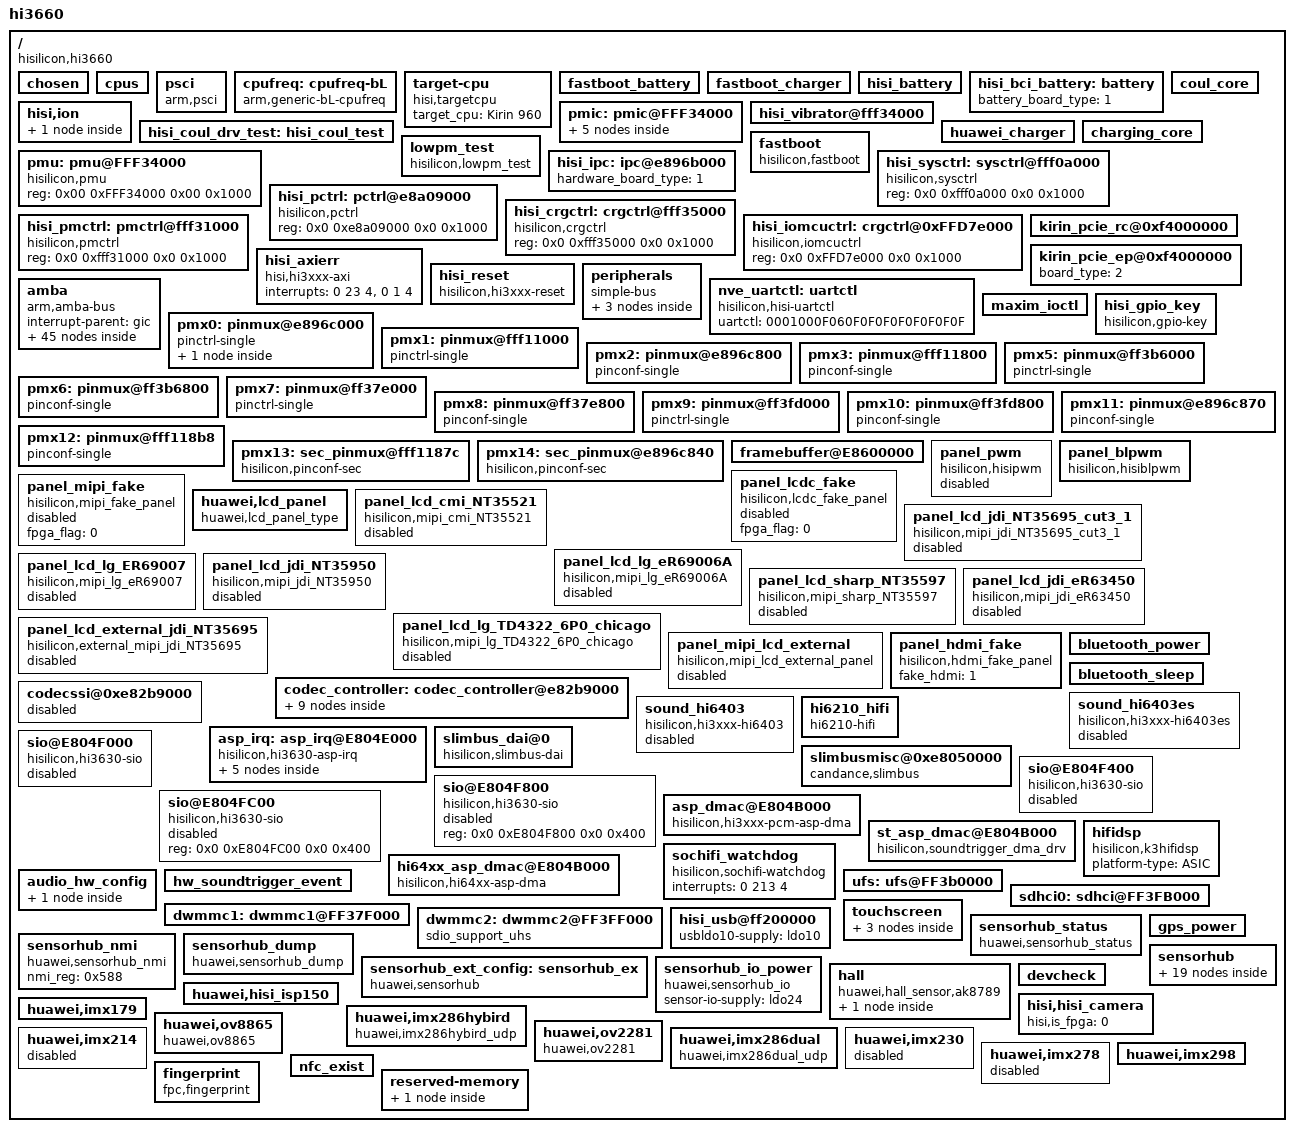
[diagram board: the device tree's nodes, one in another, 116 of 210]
/**
 * Copyright (C) 2014 Hisilicon Ltd.
 *
 *  This program is free software; you can redistribute it and/or modify
 *  it under the terms of the GNU General Public License version 2 as
 *  publishhed by the Free Software Foundation.
 */

/dts-v1/;
/include/ "fastboot.dtsi"
/include/ "hi3660_udp_default_pin.dtsi"
/include/ "hi3660_udp_default_modem_pin.dtsi"
/include/ "hisi_3660_cci.dtsi"
/include/ "hisi_3660_gic.dtsi"
/include/ "hisi_3660_timer.dtsi"
/include/ "hisi_3660.dtsi"
/include/ "hisi_3660_i2c.dtsi"
/include/ "hisi_64xx_codec.dtsi"
/include/ "hi3660_udp_default_hi6402_pin.dtsi"
/include/ "hi3660_udp_default_sec_pin.dtsi"
/include/ "hisi_bci_battery.dtsi"
/include/ "hisi_battery.dtsi"
/include/ "huawei_charger.dtsi"
/include/ "hisi_coul.dtsi"
/include/ "huawei_soft_isc.dtsi"
/include/ "fastboot_battery.dtsi"
/include/ "fastboot_charger.dtsi"
/include/ "default_3000_68k_4352.dtsi"
/include/ "hisi_3660_thermal.dtsi"
/include/ "hisi_power_ip_test.dtsi"
/include/ "huawei_devdetect.dtsi"
/include/ "hisi_3660_cpu.dtsi"
/include/ "huawei_usbswitch.dtsi"
/include/ "huawei_usbpd.dtsi"
/include/ "huawei_gps.dtsi"
/include/ "hisi_3660_framebuffer.dtsi"
/include/ "modem/hisi_modem_balong.dtsi"
/include/ "hisi_6421v500_pmic_led.dtsi"
/include/ "hisi_rtc.dtsi"
/include/ "hisi_3660_vibrator.dtsi"
/include/ "hisi_soundtrigger_event.dtsi"
/include/ "huawei_audio.dtsi"
/include/ "huawei_smartpa.dtsi"
/include/ "huawei_touchscreen.dtsi"
/include/ "hisi_3660_pca6416.dtsi"
/include/ "huawei_bluetooth.dtsi"

/ {
	#address-cells = <2>;
	#size-cells = <2>;
	model = "hi3660";
	compatible = "hisilicon,hi3660";
	interrupt-parent = <&gic>;
	hisi,boardid = <5 0 0 0>;
	hisi,boardname = "hi3660_udp_default";
	hisi,modem_id = <0x3AF5FC00>;
	hisi,product_id = <0x3AF5FC00>;

	chosen{};

	cpus {
		status = "ok";
	};

        psci {
                compatible      = "arm,psci";
                method          = "smc";
                cpu_suspend     = <0xc4000001>;
                cpu_off         = <0x84000002>;
                cpu_on          = <0xc4000003>;
                system_off      = <0x84000008>;
                system_reset    = <0x84000009>;
        };

	/* cpufreq  device */
	cpufreq: cpufreq-bL {
		compatible = "arm,generic-bL-cpufreq";
		status = "ok";
	};

	target-cpu {
		compatible = "hisi,targetcpu";
		target_cpu = "Kirin 960";
	};

	fastboot_battery:fastboot_battery {
		status = "ok";
	};
	fastboot_charger:fastboot_charger {
		hw_charger_type = <4>;
		chip_i2c_num = <6>;
		status = "ok";
	};
	hisi_battery:hisi_battery {
		status = "ok";
	};
	hisi_bci_battery:battery {
		battery_board_type = <1>; /*0:sft 1:udp 2:asic*/
		status = "ok";
	};
	coul_core:coul_core {
		adc_batt_id = <6>;
		adc_batt_temp = <10>;
		status = "ok";
	};

	hisi,ion {
		heap_sec_iris@18 {
				status = "disable";
			};
	};

	pmic:pmic@FFF34000{
		gpios = <&gpio27 6 0>;
		hisilicon,pmic_fpga_flag=<0>;
		pmic_led: pmic_led@a0 {
			status = "ok";
		};
		pmic_rtc: pmic_rtc@a0 {
			status = "ok";
		};
		ponkey:ponkey@b1{
			status = "ok";
		};
		hi6421v500_coul: hi6421v500_coul@1 {
			status = "ok";
		};
		usbvbus {
			status = "ok";
		};
	};

	hisi_vibrator@fff34000 {
		status = "ok";
	};
	hisi_coul_drv_test:hisi_coul_test {
		status = "ok";
	};
	huawei_charger: huawei_charger {
		status = "ok";
	};
	charging_core:charging_core {
		status = "ok";
		iterm = <160>;
		iin_usb = <470>;
		ichg_usb = <500>;
		ichg_fcp = <3500>;
		iin_fcp = <2000>;
		ichg_ac = <2100>;
		iin_ac = <2000>;
		inductance_para =
			"-32767", "15", "1900", "0",
			"15", "32767", "1900", "0";
	};

	fastboot {
		compatible = "hisilicon,fastboot";
		i2c3-pin = <0>;
		gpio-keyup = <205>;
		gpio-keydown = <202>;
		/*EMU_TYPE 0,FPGA 1,UDP 2,PRODUCT 3*/
		uart-board-type = <2>;
		/*UDP_TYPE 0,PRODUCT 1,FPGA 2,EMU 3*/
		lpm3-board-type = <0>;
		jtagtosd-board-type = <0>;
		motor-vib_type = <0>;

		i2c-select = <1>;
		i2c-sel0-gpio = <44>;
		i2c-sel1-gpio = <45>;
		i2c-sel0-val = <0>;
		i2c-sel1-val = <0>;
	};

	pmu: pmu@FFF34000 {
		compatible = "hisilicon,pmu";
		reg = <0x00 0xFFF34000 0x00 0x1000>;
		status = "ok";
	};

	lowpm_test {
		compatible = "hisilicon,lowpm_test";
		sr_plat_flag = <1>;
		reg = <0x0 0xfff32000 0x0 0x1000>;
		status = "ok";
	};
	hisi_ipc: ipc@e896b000 {
		hardware_board_type = <1>; /* 1:udp & fpga 0:asic */
		status = "ok";
	};

        hisi_sysctrl: sysctrl@fff0a000 {
                compatible = "hisilicon,sysctrl";
                reg = <0x0 0xfff0a000 0x0 0x1000>;
                status = "ok";
        };

        hisi_pctrl: pctrl@e8a09000 {
                compatible = "hisilicon,pctrl";
                reg = <0x0 0xe8a09000 0x0 0x1000>;
                status = "ok";
        };

        hisi_crgctrl: crgctrl@fff35000 {
                compatible = "hisilicon,crgctrl";
                reg = <0x0 0xfff35000 0x0 0x1000>;
                status = "ok";
        };

	hisi_iomcuctrl: crgctrl@0xFFD7e000 {
                compatible = "hisilicon,iomcuctrl";
                reg = <0x0 0xFFD7e000 0x0 0x1000>;
                status = "ok";
        };

        hisi_pmctrl: pmctrl@fff31000 {
                compatible = "hisilicon,pmctrl";
                reg = <0x0 0xfff31000 0x0 0x1000>;
                status = "ok";
        };

	kirin_pcie_rc@0xf4000000 {
		board_type = <2>;
		wl_power = <150>;

		/*EP Device Description: here describe BCM 4359*/
		ep_vend_id = <0x14e4>;
		ep_dev_id = <0x4355>;
		ep_ltr_latency = <0x10031003>;
		ep_l1ss_ctrl2 = <0x61>;
		status = "ok";
	};

	kirin_pcie_ep@0xf4000000 {
		board_type = <2>;
	};

	hisi_axierr {
	        compatible = "hisi,hi3xxx-axi";
	        interrupts = <0 23 4>, <0 1 4>;
	        status = "ok";
        };

    hisi_reset {
            compatible = "hisilicon,hi3xxx-reset";
            status = "ok";
        };

	peripherals {
		compatible = "simple-bus";
		#address-cells = <1>;
		#size-cells = <1>;
		ranges = <0x0 0x00000000 0x0 0xffffffff>;

		clk6250khz: clk6250khz {
			compatible = "fixed-clock";
			#clock-cells = <0>;
			clock-frequency = <6297600>;
			clock-output-names = "clk6250khz";
		};
/*
		clk4800khz: clk4800khz {
			compatible = "fixed-clock";
			#clock-cells = <0>;
			clock-frequency = <32768>;
			clock-output-names = "clk4800khz";
		};
*/

		dma0: dma@fdf30000 {
			status = "ok";
		};

		iomcu_dma: dma@ffd77000 {
			status = "ok";
		};

	};
	nve_uartctl:uartctl {
		compatible = "hisilicon,hisi-uartctl";
		uartctl = "0001000F060F0F0F0F0F0F0F0F";
	};
	amba {
		#address-cells = <2>;
		#size-cells = <2>;
		compatible = "arm,amba-bus";
		interrupt-parent = <&gic>;
		ranges;

		/*rtc0: rtc@FFF04000 {
				compatible = "arm,rtc-pl031", "arm,primecell";
				reg = <0xfff04000 0x1000>;
				interrupts = <0 46 0x4>;
				clocks = <&pclk>;
				clock-names = "apb_pclk";
				status = "ok";
		};*/

		/*rtc1: rtc@FFF05000 {
				compatible = "arm,rtc-pl031", "arm,primecell";
				reg = <0xfff05000 0x1000>;
				interrupts = <0 47 0x4>;
				clocks = <&pclk>;
				clock-names = "apb_pclk";
				status = "ok";
		};*/

		watchdog0 {
			compatible = "arm,sp805", "arm,primecell";
			reg = <0x0 0xe8a06000 0x0 0x1000>;
			default-timeout = <24>;
			interrupts = <0 44 4>;
			clocks = <&pclk_gate_wd0 &pclk>;
			clock-names = "pclk_wd0", "apb_pclk";
			status = "disabled";
		};

                iomcu_watchdog: watchdog@ffd7c000{
                        compatible = "hisilicon,iomcu-watchdog";
                        reg = <0x0 0xFFD7C000 0x0 0x1000>;
                        status = "ok";
                };

		/*wdt1@e8a07000 {
			compatible = "arm,sp805", "arm,primecell";
			reg = <0x0 0xe8a07000 0x0 0x1000>;
			interrupts = <0 45 4>;
			clocks = <&pclk_gate_wd0 &pclk>;
			clock-names = "pclk_wd0", "apb_pclk";
		};*/

		serial0: uart@fdf02000 {
			pinctrl-names = "default", "idle";
			pinctrl-0 = <&gpio053_pmx_func &gpio054_pmx_func &gpio053_cfg_func &gpio054_cfg_func>;
			pinctrl-1 = <&gpio053_pmx_idle &gpio054_pmx_idle &gpio053_cfg_idle &gpio054_cfg_idle>;
			dma-names = "", "";
			dmas = <>;
			clock-rate = <0 19200000>;
			console-fifo-enable = <1>;
			console-fifo-size = <262144>;/* 256k */
			console-fifo-cpuon = <3>;
			status = "ok";
		};

		serial1: uart@fdf00000 {
			pinctrl-names = "default", "idle";
			pinctrl-0 = <>;
			pinctrl-1 = <>;
			clock-rate = <0 160000000>;
			status = "disabled";
			reset-enable-flag = <1>;
		};

		serial2: uart@fdf03000 {
			pinctrl-names = "default", "idle";
			pinctrl-0 = <>;
			pinctrl-1 = <>;
			clock-rate = <0 160000000>;
			status = "ok";
			reset-enable-flag = <1>;
		};

		serial3: uart@ffd74000 {
			pinctrl-names = "default", "idle";
			pinctrl-0 = <&gpio057_pmx_func &gpio058_pmx_func &gpio059_pmx_func &gpio060_pmx_func &gpio057_cfg_func &gpio058_cfg_func &gpio059_cfg_func &gpio060_cfg_func>;
			pinctrl-1 = <&gpio057_pmx_idle &gpio058_pmx_idle &gpio059_pmx_idle &gpio060_pmx_idle &gpio057_cfg_idle &gpio058_cfg_idle &gpio059_cfg_idle &gpio060_cfg_idle>;
			dma-names = "", "";
			dmas = <>;
			clock-rate = <0 100000000>;
			status = "ok";
			reset-enable-flag = <0>;
		};

		serial4: uart@fdf01000 {
			pinctrl-names = "default", "idle";
			pinctrl-0 = <&gpio061_pmx_func &gpio062_pmx_func &gpio063_pmx_func &gpio064_pmx_func &gpio061_cfg_func &gpio062_cfg_func &gpio063_cfg_func &gpio064_cfg_func>;
			pinctrl-1 = <&gpio061_pmx_idle &gpio062_pmx_idle &gpio063_pmx_idle &gpio064_pmx_idle &gpio061_cfg_idle &gpio062_cfg_idle &gpio063_cfg_idle &gpio064_cfg_idle>;
			clock-rate = <0 160000000>;
			status = "ok";
			reset-enable-flag = <1>;
		};

		serial5: uart@fdf05000 {
			pinctrl-names = "default", "idle";
			pinctrl-0 = <>;
			pinctrl-1 = <>;
			clock-rate = <0 160000000>;
			status = "ok";
			reset-enable-flag = <1>;
		};

		serial6: uart@fff32000 {
			pinctrl-names = "default", "idle";
			pinctrl-0 = <&gpio055_pmx_func &gpio056_pmx_func &gpio055_cfg_func &gpio056_cfg_func>;
			pinctrl-1 = <&gpio055_pmx_idle &gpio056_pmx_idle &gpio055_cfg_idle &gpio056_cfg_idle>;
			clock-rate = <0 19200000>;
			console-fifo-enable = <1>;
			console-fifo-size = <262144>;/* 256k */
			console-fifo-cpuon = <3>;
			status = "ok";
		};
		dx_cc63p: dx_cc63p@fdf0e000 {
			compatible = "dx,cc63p";
			reg = <0x0 0xfdf0e000 0x0 0x1000>;
			interrupt-parent = <&gic>;
			interrupts = <0 135 4>;
			status = "ok";
		};

		spi0: spi@ffd70000 {
			status = "ok";
			clock-rate = <0 32000000>;
			pinctrl-names = "default", "idle";
			pinctrl-0 = <&gpio044_pmx_func &gpio045_pmx_func &gpio046_pmx_func &gpio044_cfg_func &gpio045_cfg_func
					&gpio046_cfg_func>;
			pinctrl-1 = <&gpio044_pmx_idle &gpio045_pmx_idle &gpio046_pmx_idle &gpio044_cfg_idle &gpio045_cfg_idle
					&gpio046_cfg_idle>;
			spi_dev0: spi_dev0@0 {
					compatible = "spi_dev0";
					spi-max-frequency = <30000000>;
					reg = <0>;
					pl022,com-mode = <0>;
					pl022,interface = <0>;
					pl022,rx-level-trig = <3>;
					pl022,tx-level-trig = <3>;
					pl022,ctrl-len = <7>;
					pl022,wait-state = <0>;
					pl022,duplex = <0>;
					pl022,slave-tx-disable = <0>;
			};

			spi_dev1: spi_dev1@1 {
					compatible = "spi_dev1";
					spi-max-frequency = <13000000>;
					reg = <1>;
					pl022,com-mode = <1>;
					pl022,interface = <0>;
					pl022,rx-level-trig = <3>;
					pl022,tx-level-trig = <3>;
					pl022,ctrl-len = <7>;
					pl022,wait-state = <0>;
					pl022,duplex = <0>;
					pl022,slave-tx-disable = <0>;
			};

			spi_dev2: spi_dev2@2 {
					compatible = "spi_dev2";
					spi-max-frequency = <13000000>;
					reg = <2>;
					pl022,com-mode = <2>;
					pl022,interface = <0>;
					pl022,rx-level-trig = <3>;
					pl022,tx-level-trig = <3>;
					pl022,ctrl-len = <7>;
					pl022,wait-state = <0>;
					pl022,duplex = <0>;
					pl022,slave-tx-disable = <0>;
			};

			spi_dev3: spi_dev3@3 {
					compatible = "spi_dev3";
					spi-max-frequency = <13000000>;
					reg = <3>;
					pl022,com-mode = <0>;
					pl022,interface = <0>;
					pl022,rx-level-trig = <3>;
					pl022,tx-level-trig = <3>;
					pl022,ctrl-len = <7>;
					pl022,wait-state = <0>;
					pl022,duplex = <0>;
					pl022,slave-tx-disable = <0>;
			};
		};

		spi1: spi@fdf08000 {
			/* secure */
			status = "ok";
			clock-rate = <0 46000000>;
			pinctrl-names = "default", "idle";
			pinctrl-0 = <>;
			pinctrl-1 = <>;
			spi_dev10: spi_dev10@10 {
					compatible = "spi_dev10";
					spi-max-frequency = <24000000>;
					reg = <0>;
					pl022,com-mode = <0>;
					pl022,interface = <0>;
					pl022,rx-level-trig = <3>;
					pl022,tx-level-trig = <3>;
					pl022,ctrl-len = <7>;
					pl022,wait-state = <0>;
					pl022,duplex = <0>;
					pl022,slave-tx-disable = <0>;
			};
		};

		spi3: spi@ff3b3000 {
			status = "ok";
			clock-rate = <0 80000000>;
			pinctrl-names = "default", "idle";
			pinctrl-0 = <>;
			pinctrl-1 = <>;
			spi_dev30: spi_dev30@30 {
					compatible = "spi_dev30";
					spi-max-frequency = <30000000>;
					reg = <0>;
					pl022,com-mode = <2>;
					pl022,interface = <0>;
					pl022,rx-level-trig = <3>;
					pl022,tx-level-trig = <3>;
					pl022,ctrl-len = <7>;
					pl022,wait-state = <0>;
					pl022,duplex = <0>;
					pl022,slave-tx-disable = <0>;
			};

			spi_dev31: spi_dev31@31 {
					compatible = "spi_dev31";
					spi-max-frequency = <13000000>;
					reg = <1>;
					pl022,com-mode = <1>;
					pl022,interface = <0>;
					pl022,rx-level-trig = <3>;
					pl022,tx-level-trig = <3>;
					pl022,ctrl-len = <7>;
					pl022,wait-state = <0>;
					pl022,duplex = <0>;
					pl022,slave-tx-disable = <0>;
			};

			spi_dev32: spi_dev32@32 {
					compatible = "spi_dev32";
					spi-max-frequency = <13000000>;
					reg = <2>;
					pl022,com-mode = <2>;
					pl022,interface = <0>;
					pl022,rx-level-trig = <3>;
					pl022,tx-level-trig = <3>;
					pl022,ctrl-len = <7>;
					pl022,wait-state = <0>;
					pl022,duplex = <0>;
					pl022,slave-tx-disable = <0>;
			};

			spi_dev33: spi_dev33@33 {
					compatible = "spi_dev33";
					spi-max-frequency = <13000000>;
					reg = <3>;
					pl022,com-mode = <0>;
					pl022,interface = <0>;
					pl022,rx-level-trig = <3>;
					pl022,tx-level-trig = <3>;
					pl022,ctrl-len = <7>;
					pl022,wait-state = <0>;
					pl022,duplex = <0>;
					pl022,slave-tx-disable = <0>;
			};
		};
		spi4: spi@fdf06000 {
			/* secure */
			status = "ok";
			clock-rate = <0 46000000>;
			pinctrl-names = "default", "idle";
			pinctrl-0 = <>;
			pinctrl-1 = <>;
			spi_dev40: spi_dev40@40 {
					compatible = "spi_dev40";
					spi-max-frequency = <5000000>;
					reg = <0>;
					pl022,com-mode = <2>;
					pl022,interface = <0>;
					pl022,rx-level-trig = <3>;
					pl022,tx-level-trig = <3>;
					pl022,ctrl-len = <7>;
					pl022,wait-state = <0>;
					pl022,duplex = <0>;
					pl022,slave-tx-disable = <0>;
			};

			spi_dev41: spi_dev41@41 {
					compatible = "spi_dev41";
					spi-max-frequency = <13000000>;
					reg = <1>;
					pl022,com-mode = <1>;
					pl022,interface = <0>;
					pl022,rx-level-trig = <3>;
					pl022,tx-level-trig = <3>;
					pl022,ctrl-len = <7>;
					pl022,wait-state = <0>;
					pl022,duplex = <0>;
					pl022,slave-tx-disable = <0>;
			};

			spi_dev42: spi_dev42@42 {
					compatible = "spi_dev42";
					spi-max-frequency = <13000000>;
					reg = <2>;
					pl022,com-mode = <2>;
					pl022,interface = <0>;
					pl022,rx-level-trig = <3>;
					pl022,tx-level-trig = <3>;
					pl022,ctrl-len = <7>;
					pl022,wait-state = <0>;
					pl022,duplex = <0>;
					pl022,slave-tx-disable = <0>;
			};

			spi_dev43: spi_dev43@43 {
					compatible = "spi_dev43";
					spi-max-frequency = <13000000>;
					reg = <3>;
					pl022,com-mode = <0>;
					pl022,interface = <0>;
					pl022,rx-level-trig = <3>;
					pl022,tx-level-trig = <3>;
					pl022,ctrl-len = <7>;
					pl022,wait-state = <0>;
					pl022,duplex = <0>;
					pl022,slave-tx-disable = <0>;
			};
		};

		/* I2C0 ~ I2C */
		i2c0: i2c@FFD71000 {
			status = "disabled";
			clock-rate = <0 32000000>;
			pinctrl-names = "default", "idle";
			pinctrl-0 = <>;
			pinctrl-1 = <>;
			//cs-gpios = <>, <>;
		};

		i2c1: i2c@FFD72000 {
			status = "disabled";
			clock-rate = <0 32000000>;
			pinctrl-names = "default", "idle";
			pinctrl-0 = <>;
			pinctrl-1 = <>;
			//cs-gpios = <>, <>;
		};

		i2c2: i2c@FFD73000 {
			status = "disabled";
			clock-rate = <0 32000000>;
			pinctrl-names = "default", "idle";
			pinctrl-0 = <&gpio187_pmx_func &gpio188_pmx_func &gpio187_cfg_func &gpio188_cfg_func>;
			pinctrl-1 = <&gpio187_pmx_idle &gpio188_pmx_idle &gpio187_cfg_idle &gpio188_cfg_idle>;
			cs-gpios = <&gpio23 3 0>, <&gpio23 4 0>;
		};

		i2c3: i2c@FDF0C000 {
			status = "ok";
			clock-rate = <0 107000000>;
			pinctrl-names = "default", "idle";
			pinctrl-0 = <&gpio013_pmx_func &gpio014_pmx_func &gpio013_cfg_func &gpio014_cfg_func>;
			pinctrl-1 = <&gpio013_pmx_idle &gpio014_pmx_idle &gpio013_cfg_idle &gpio014_cfg_idle>;
			cs-gpios = <&gpio1 5 0>, <&gpio1 6 0>;

			gpio33: pca6416-gpio@20{
				status = "ok";
			};

			huawei,lm3642@63{
				compatible = "huawei,lm3642";
				reg = <0x63>;
				huawei,flash-name = "lm3642";
				huawei,flash-index = <2>;
				huawei,flash-type = <0>;
				huawei,slave-address = <0x63>;
				huawei,need-wakelock = <1>;
				huawei,flash-chipid = <0x00>;
				huawei,flash_current = <7>;
				status = "ok";
				huawei,irq_gpio = <21>;
			};
		};

		i2c4: i2c@FDF0D000 {
			status = "ok";
			clock-rate = <0 107000000>;
			pinctrl-names = "default", "idle";
			pinctrl-0 = <&gpio038_pmx_func &gpio039_pmx_func &gpio038_cfg_func &gpio039_cfg_func>;
			pinctrl-1 = <&gpio038_pmx_idle &gpio039_pmx_idle &gpio038_cfg_idle &gpio039_cfg_idle>;
			cs-gpios = <&gpio4 6 0>, <&gpio4 7 0>;

			pn547_nfc: nfc@28{
				status = "ok";
				nfc_on_type = "hisi_pmic";
				nfc_brcm_conf_name = "libnfc_brcm_hi3660_udp_pn548.conf";
				nfc_nxp_name = "libnfc_nxp_hi3660_udp_pn548.conf";
				nfc_card_num = <0x2>;
				clk_status ="ok";
				pn547,dload = <&gpio6 0 0>;
				pn547,irq = <&gpio24 3 0>;
				pinctrl-1 = <&gpio179_pmx_idle &gpio179_cfg_idle &gpio048_pmx_idle &gpio195_pmx_idle>;
				pinctrl-0 = <&gpio179_pmx_func &gpio179_cfg_func &gpio048_pmx_func &gpio195_pmx_func>;
				pinctrl-names = "default","idle";
				clock-names = "clk_out0";
				clocks = <&clk_gate_out0>;
				reg = <0x28>;
				compatible = "hisilicon,pn547_nfc";
				nfc_chip_type = "pn548";
				nfc_single_channel = "true";
				nfc_ese_type = "hisee";
			};

			hisi,ncp6925@50{
				compatible = "hisi,ncp6925";
				reg = <0x50>;
				hisi,pmic_name = "ncp6925";
				hisi,pmic_index = <0>;
				hisi,slave_address = <0x50>;
				hisi,pmic-pin = <268 999 999>;
				hisi,pmic-voltage = <0x0 0x1 0x2 0x3 0x4 0x5 0x6>;
				status = "ok";
			};

			huawei,lm3646@67{
				status = "ok";
				huawei,need-wakelock = <1>;
				pinctrl-names = "default", "idle";
				pinctrl-0 = <&gpio171_pmx_func &gpio171_cfg_func>;
				pinctrl-1 = <&gpio171_pmx_idle &gpio171_cfg_idle>;
				pinctrl-names = "default", "idle";
				huawei,flash-pin = <171 999 999>;
			};
			huawei,mp3336@27{
				status = "ok";
				huawei,need-wakelock = <1>;
				pinctrl-names = "default", "idle";
				pinctrl-0 = <&gpio171_pmx_func &gpio171_cfg_func>;
				pinctrl-1 = <&gpio171_pmx_idle &gpio171_cfg_idle>;
				pinctrl-names = "default", "idle";
				huawei,flash-pin = <171 999 999>;
			};

			max98925_smartpa_l:smartpa@31 {
				status = "ok";
				gain_incall = <0x16>;
				gain = <0x16>;
				iv_slot_change = <1>;
			};

			max98925_smartpa_r:smartpa@34 {
				status = "disabled";
				gain_incall = <0x2d>;
				gain = <0x36>;
				iv_slot_change = <0>;
			};

			tps65132_phy: tps65132@3e {
				compatible = "hisilicon,tps65132_phy";
				reg = <0x3e>;
				gpios = <&gpio15 5 0>, <&gpio4 5 0>;
				status = "ok";
			};
		};

		i2c6: i2c@FFD6A000 {
			status = "ok";
			clock-rate = <0 32000000>;
			pinctrl-names = "default", "idle";
			pinctrl-0 = <&gpio197_pmx_func &gpio196_pmx_func &gpio197_cfg_func &gpio196_cfg_func>;
			pinctrl-1 = <&gpio197_pmx_idle &gpio196_pmx_idle &gpio197_cfg_idle &gpio196_cfg_idle>;
			cs-gpios = <&gpio24 5 0>, <&gpio24 4 0>;
			hi6523_charger_i2c6: hi6523_charger_i2c6@6B{
				status = "ok";
				fcp_support = <0>;
				vclamp = <192>;
				bat_comp = <45>;
			};

			fairchild_fsa9685_i2c6: fsa9685_i2c6@25 {
				usbid-enable = <1>;
				status = "ok";
			};
		};

		i2c7: i2c@FDF0B000 {
			status = "ok";
			clock-rate = <0 107000000>;
			pinctrl-names = "default", "idle";
			pinctrl-0 = <&gpio187_pmx_func &gpio188_pmx_func &gpio187_cfg_func &gpio188_cfg_func>;
			pinctrl-1 = <&gpio187_pmx_idle &gpio188_pmx_idle &gpio187_cfg_idle &gpio188_cfg_idle>;
			cs-gpios = <&gpio23 3 0>, <&gpio23 4 0>;
		};
	};
	/* end amba */

	maxim_ioctl {
		status = "ok";
	};

	hisi_gpio_key {
		compatible = "hisilicon,gpio-key";
		pinctrl-names = "default", "idle";
		pinctrl-0 = <&gpio205_cfg_func &gpio202_cfg_func>;
		pinctrl-1 = <&gpio205_cfg_idle &gpio202_cfg_idle>;
		gpio-keyup,gpio-irq = <&gpio25 5 0>;
		gpio-keydown,gpio-irq = <&gpio25 2 0>;
		status = "ok";
	};

	pmx0: pinmux@e896c000 {
		compatible = "pinctrl-single", "pinctrl-single0";
		reg = <0x0 0xe896c000 0x0 0x1f0>;
		#gpio-range-cells = <3>;
		//ranges;
		pinctrl-single,register-width = <32>;
		pinctrl-single,function-mask = <7>;
		/* pin base, nr pins & gpio function */
		pinctrl-single,gpio-range = <&range 0 13 0 &range 25 95  0>;
		range: gpio-range {
			#pinctrl-single,gpio-range-cells = <3>;
		};
	};

	pmx1: pinmux@fff11000 {
		compatible = "pinctrl-single", "pinctrl-single1";
		reg = <0x0 0xfff11000 0x0 0x0a8>;
		#gpio-range-cells = <3>;
		//ranges;
		pinctrl-single,register-width = <32>;
		pinctrl-single,function-mask = <7>;
		pinctrl-single,gpio-range = <&range 0 27 0>;
		/* pin base, nr pins & gpio function */
	};

	pmx2: pinmux@e896c800 {
		compatible = "pinconf-single", "pinctrl-singlei2";
		reg = <0x0 0xe896c800 0x0 0x40>;
		//ranges;
		pinctrl-single,register-width = <32>;
	};

	pmx3: pinmux@fff11800 {
		compatible = "pinconf-single", "pinctrl-single4";
		reg = <0x0 0xfff11800 0x0 0x7c>;
		//ranges;
		pinctrl-single,register-width = <32>;
	};

	pmx5:pinmux@ff3b6000 {
		compatible = "pinctrl-single", "pinctrl-single5";
		reg = <0x0 0xff3b6000 0x0 0x030>;
		pinctrl-single,register-width = <32>;
		pinctrl-single,function-mask = <7>;
		pinctrl-single,gpio-range = <&range 0 12 0>;
	};

	pmx6:pinmux@ff3b6800 {
		compatible = "pinconf-single", "pinctrl-single6";
		reg = <0x0 0xff3b6800 0x0 0x030>;
		pinctrl-single,register-width = <32>;
	};

	pmx7:pinmux@ff37e000 {
		compatible = "pinctrl-single", "pinctrl-single7";
		reg = <0x0 0xff37e000 0x0 0x018>;
		pinctrl-single,register-width = <32>;
		pinctrl-single,function-mask = <7>;
		pinctrl-single,gpio-range = <&range 0 6 0>;
	};

	pmx8:pinmux@ff37e800 {
		compatible = "pinconf-single", "pinctrl-single8";
		reg = <0x0 0xff37e800 0x0 0x018>;
		pinctrl-single,register-width = <32>;
	};

	pmx9:pinmux@ff3fd000 {
		compatible = "pinctrl-single", "pinctrl-single9";
		reg = <0x0 0xff3fd000 0x0 0x018>;
		pinctrl-single,register-width = <32>;
		pinctrl-single,function-mask = <7>;
		pinctrl-single,gpio-range = <&range 0 6 0>;
	};

	pmx10:pinmux@ff3fd800 {
		compatible = "pinconf-single", "pinctrl-single10";
		reg = <0x0 0xff3fd800 0x0 0x01c>;
		pinctrl-single,register-width = <32>;
	};

	pmx11: pinmux@e896c870 {
		compatible = "pinconf-single", "pinctrl-singlei2";
		reg = <0x0 0xe896c870 0x0 0x19c>;
		//ranges;
		pinctrl-single,register-width = <32>;
	};

	pmx12: pinmux@fff118b8 {
		compatible = "pinconf-single", "pinctrl-singlei2";
		reg = <0x0 0xfff118b8 0x0 0x4>;
		//ranges;
		pinctrl-single,register-width = <32>;
	};


	pmx13:sec_pinmux@fff1187c {
		compatible = "hisilicon,pinconf-sec";
		reg = <0x0 0xfff1187c 0x0 0x3c>;
		pinctrl-single,register-width = <32>;
	};

	pmx14:sec_pinmux@e896c840 {
		compatible = "hisilicon,pinconf-sec";
		reg = <0x0 0xe896c840 0x0 0x2C>;
		pinctrl-single,register-width = <32>;
	};

	/* display start */
	framebuffer@E8600000 {
		fpga_flag = <0>;
		lcd_xres = <1080>;
		lcd_yres = <1920>;
		lcd_fps = <60>;
	};

	panel_pwm {
		#address-cells = <2>;
		#size-cells = <2>;
		compatible = "hisilicon,hisipwm";
		reg = <0 0xE8A04000 0 0x1000>;
		clocks = <&clk_gate_pwm>;
		clock-names = "clk_pwm";
		pinctrl-names = "default","idle";
		pinctrl-0 = <&gpio181_pmx_func &gpio182_pmx_func &gpio181_cfg_func &gpio182_cfg_func>;
		pinctrl-1 = <&gpio181_pmx_idle &gpio182_pmx_idle &gpio181_cfg_idle &gpio182_cfg_idle>;
		fpga_flag = <0>;
		status = "disabled";
	};

	panel_blpwm {
		#address-cells = <2>;
		#size-cells = <2>;
		compatible = "hisilicon,hisiblpwm";
		reg = <0 0xFFD75000 0 0x1000>;
		clocks = <&clk_gate_blpwm>;
		clock-names = "clk_blpwm";
		pinctrl-names = "default","idle";
		pinctrl-0 = <&gpio181_pmx_func &gpio182_pmx_func &gpio181_cfg_func &gpio182_cfg_func>;
		pinctrl-1 = <&gpio181_pmx_idle &gpio182_pmx_idle &gpio181_cfg_idle &gpio182_cfg_idle>;
		fpga_flag = <0>;
		status = "ok";
	};

	panel_lcdc_fake {
		#address-cells = <2>;
		#size-cells = <2>;
		compatible = "hisilicon,lcdc_fake_panel";
		fpga_flag = <0>;
		status = "disabled";
	};

	panel_mipi_fake {
		#address-cells = <2>;
		#size-cells = <2>;
		compatible = "hisilicon,mipi_fake_panel";
		fpga_flag = <0>;
		status = "disabled";
	};

	huawei,lcd_panel {
		compatible = "huawei,lcd_panel_type";
		detect_type = <0>;		/*0:DETECT_GPIOID  1:DETECT_CHIPID  2:DETECT_LCD_TYPE */
		gpio_id = <33>;
		gpio_cfg_addr = <0xE896C888>;
		support_lcd_type = "JDI_NT35695_CUT3_1_LCD","LG_ER69006A_LCD";
		lcd_id_match_tab = <0 1>;
	};

	panel_lcd_cmi_NT35521 {
		#address-cells = <2>;
		#size-cells = <2>;
		compatible = "hisilicon,mipi_cmi_NT35521";
		//2:PWM,  4:BLPWM,  8:MIPI
		lcd-bl-type = <8>;
		//8:PANEL_MIPI_VIDEO,  16:PANEL_MIPI_CMD
		lcd-display-type = <8>;
		//0:IFBC_TYPE_NONE
		lcd-ifbc-type = <0>;
		//gpio_lcd_vcc1v8, gpio_lcd_p5v5_enable, gpio_lcd_n5v5_enable, gpio_lcd_reset, gpio_lcd_bl_enable
		gpios = <&gpio6 2 0>, <&gpio6 0 0>,  <&gpio8 7 0>, <&gpio7 3 0>, <&gpio8 6 0>;
		gpio_nums = <50 48 71 59 70>;
		//lcdio-vcc-supply = <&ldo4>;
		//lcdanalog-vcc-supply = <&ldo17>;
		//pinctrl-names = "default", "idle";
		//pinctrl-0 = <&gpio021_pmx_func &gpio021_cfg_func &gpio009_cfg_func &gpio010_cfg_func &gpio015_cfg_func &gpio020_cfg_func>;
		//pinctrl-1 = <&gpio021_pmx_idle &gpio021_cfg_idle &gpio009_cfg_idle &gpio010_cfg_idle &gpio015_cfg_idle &gpio020_cfg_idle>;
		fpga_flag = <0>;
		status = "disabled";
	};

	panel_lcd_jdi_NT35695_cut3_1 {
		#address-cells = <2>;
		#size-cells = <2>;
		compatible = "hisilicon,mipi_jdi_NT35695_cut3_1";
		//2:PWM,  4:BLPWM,  8:MIPI
		lcd-bl-type = <4>;
		//8:PANEL_MIPI_VIDEO,  16:PANEL_MIPI_CMD
		lcd-display-type = <16>;
		//0:IFBC_TYPE_NONE 7:IFBC_TYPE_VESA3X_SINGLE 9:IFBC_TYPE_VESA3X_DUAL
		lcd-ifbc-type = <0>;
		//gpio_lcd_p5v5_enable, gpio_lcd_n5v5_enable, gpio_lcd_bl_enable, gpio_lcd_reset,  gpio_lcd_te0
		gpios = <&gpio15 5 0>, <&gpio4 5 0>,  <&gpio11 0 0>,  <&gpio5 0 0>, <&gpio2 7 0>;
		//gpio_lcd_p5v5_enable, gpio_lcd_n5v5_enable, gpio_lcd_bl_enable, gpio_lcd_reset,  gpio_lcd_te0, ID0, tp_reset
		gpio_nums = <125 37 88 40 23 33 65>;
		lcdio-vcc-supply = <&ldo4>;
		lcdanalog-vcc-supply = <&ldo17>;
		pinctrl-names = "default", "idle";
		pinctrl-0 = <&gpio125_pmx_func &gpio037_pmx_func &gpio088_pmx_func &gpio040_pmx_func &gpio125_cfg_func &gpio037_cfg_func &gpio088_cfg_func &gpio040_cfg_func>;
		pinctrl-1 = <&gpio125_pmx_idle &gpio037_pmx_idle &gpio088_pmx_idle &gpio040_pmx_idle &gpio125_cfg_idle &gpio037_cfg_idle &gpio088_cfg_idle &gpio040_cfg_idle>;
		vsp-vsn-voltage = <15>;
		fpga_flag = <0>;
		status = "disabled";
	};

	panel_lcd_lg_eR69006A {
		#address-cells = <2>;
		#size-cells = <2>;
		compatible = "hisilicon,mipi_lg_eR69006A";
		lcd-bl-type = <4>;
		//8:PANEL_MIPI_VIDEO,  16:PANEL_MIPI_CMD
		lcd-display-type = <16>;
		lcd-ifbc-type = <0>;
		//gpio_lcd_p5v5_enable, gpio_lcd_n5v5_enable, gpio_lcd_bl_enable, gpio_lcd_reset,  gpio_lcd_te0
		gpios = <&gpio15 5 0>, <&gpio4 5 0>,  <&gpio11 0 0>,  <&gpio5 0 0>, <&gpio2 7 0>;
		//gpio_lcd_p5v5_enable, gpio_lcd_n5v5_enable, gpio_lcd_bl_enable, gpio_lcd_reset,  gpio_lcd_te0, ID0, tp_reset
		gpio_nums = <125 37 88 40 23 33 65>;
		lcdio-vcc-supply = <&ldo4>;
		lcdanalog-vcc-supply = <&ldo17>;
		pinctrl-names = "default", "idle";
		pinctrl-0 = <&gpio125_pmx_func &gpio037_pmx_func &gpio088_pmx_func &gpio040_pmx_func &gpio125_cfg_func &gpio037_cfg_func &gpio088_cfg_func &gpio040_cfg_func>;
		pinctrl-1 = <&gpio125_pmx_idle &gpio037_pmx_idle &gpio088_pmx_idle &gpio040_pmx_idle &gpio125_cfg_idle &gpio037_cfg_idle &gpio088_cfg_idle &gpio040_cfg_idle>;
		vsp-vsn-voltage = <15>;
		fpga_flag = <0>;
		status = "disabled";
	};

	panel_lcd_lg_ER69007 {
		#address-cells = <2>;
		#size-cells = <2>;
		compatible = "hisilicon,mipi_lg_eR69007";
		//2:PWM,  4:BLPWM,  8:MIPI
		lcd-bl-type = <4>;
		//8:PANEL_MIPI_VIDEO,  16:PANEL_MIPI_CMD
		lcd-display-type = <16>;
		lcd-ifbc-type = <5>;
		//gpio_lcd_p5v5_enable, gpio_lcd_n5v5_enable, gpio_lcd_bl_enable, gpio_lcd_reset,  gpio_lcd_te0
		gpios = <&gpio15 5 0>, <&gpio4 5 0>,  <&gpio11 0 0>,  <&gpio5 0 0>, <&gpio2 7 0>;
		//gpio_lcd_p5v5_enable, gpio_lcd_n5v5_enable, gpio_lcd_bl_enable, gpio_lcd_reset,  gpio_lcd_te0, ID0, tp_reset
		gpio_nums = <125 37 88 40 23 33 65>;
		lcdio-vcc-supply = <&ldo4>;
		lcdanalog-vcc-supply = <&ldo17>;
		pinctrl-names = "default", "idle";
		pinctrl-0 = <&gpio125_pmx_func &gpio037_pmx_func &gpio088_pmx_func &gpio040_pmx_func &gpio125_cfg_func &gpio037_cfg_func &gpio088_cfg_func &gpio040_cfg_func>;
		pinctrl-1 = <&gpio125_pmx_idle &gpio037_pmx_idle &gpio088_pmx_idle &gpio040_pmx_idle &gpio125_cfg_idle &gpio037_cfg_idle &gpio088_cfg_idle &gpio040_cfg_idle>;
		vsp-vsn-voltage = <15>;
		fpga_flag = <0>;
		status = "disabled";
             };
	panel_lcd_jdi_NT35950 {
		#address-cells = <2>;
		#size-cells = <2>;
		compatible = "hisilicon,mipi_jdi_NT35950";
		//2:PWM,  4:BLPWM,  8:MIPI
		lcd-bl-type = <4>;
		//8:PANEL_MIPI_VIDEO,  16:PANEL_MIPI_CMD ,64:PANEL_DUAL_MIPI_CMD
		lcd-display-type = <64>;
		//0:IFBC_TYPE_NONE 7:IFBC_TYPE_VESA3X_SINGLE 9:IFBC_TYPE_VESA3X_DUAL
		lcd-ifbc-type = <9>;
		//gpio_lcd_p5v5_enable, gpio_lcd_n5v5_enable, gpio_lcd_bl_enable, gpio_lcd_reset,  gpio_lcd_te0
		gpios = <&gpio15 5 0>, <&gpio4 5 0>,  <&gpio11 0 0>,  <&gpio5 0 0>, <&gpio2 7 0>;
		//gpio_lcd_p5v5_enable, gpio_lcd_n5v5_enable, gpio_lcd_bl_enable, gpio_lcd_reset,  gpio_lcd_te0, ID0, tp_reset
		gpio_nums = <125 37 88 40 23 33 65>;
		lcdio-vcc-supply = <&ldo4>;
		lcdanalog-vcc-supply = <&ldo17>;
		pinctrl-names = "default", "idle";
		pinctrl-0 = <&gpio125_pmx_func &gpio037_pmx_func &gpio088_pmx_func &gpio040_pmx_func &gpio125_cfg_func &gpio037_cfg_func &gpio088_cfg_func &gpio040_cfg_func>;
		pinctrl-1 = <&gpio125_pmx_idle &gpio037_pmx_idle &gpio088_pmx_idle &gpio040_pmx_idle &gpio125_cfg_idle &gpio037_cfg_idle &gpio088_cfg_idle &gpio040_cfg_idle>;
		vsp-vsn-voltage = <15>;
		fpga_flag = <0>;
		status = "disabled";
	};

	panel_lcd_sharp_NT35597 {
		#address-cells = <2>;
		#size-cells = <2>;
		compatible = "hisilicon,mipi_sharp_NT35597";
		//2:PWM,  4:BLPWM,  8:MIPI
		lcd-bl-type = <4>;
		//8:PANEL_MIPI_VIDEO,  16:PANEL_MIPI_CMD ,32:PANEL_DUAL_MIPI_VIDEO, 64:PANEL_DUAL_MIPI_CMD
		lcd-display-type = <32>;
		//0:IFBC_TYPE_NONE 7:IFBC_TYPE_VESA3X_SINGLE 9:IFBC_TYPE_VESA3X_DUAL
		lcd-ifbc-type = <0>;
		//gpio_lcd_p5v5_enable, gpio_lcd_n5v5_enable, gpio_lcd_bl_enable, gpio_lcd_reset,  gpio_lcd_te0
		gpios = <&gpio15 5 0>, <&gpio4 5 0>,  <&gpio11 0 0>,  <&gpio5 0 0>, <&gpio2 7 0>;
		//gpio_lcd_p5v5_enable, gpio_lcd_n5v5_enable, gpio_lcd_bl_enable, gpio_lcd_reset,  gpio_lcd_te0, ID0, tp_reset
		gpio_nums = <125 37 88 40 23 33 65>;
		lcdio-vcc-supply = <&ldo4>;
		lcdanalog-vcc-supply = <&ldo17>;
		pinctrl-names = "default", "idle";
		pinctrl-0 = <&gpio125_pmx_func &gpio037_pmx_func &gpio088_pmx_func &gpio040_pmx_func &gpio125_cfg_func &gpio037_cfg_func &gpio088_cfg_func &gpio040_cfg_func>;
		pinctrl-1 = <&gpio125_pmx_idle &gpio037_pmx_idle &gpio088_pmx_idle &gpio040_pmx_idle &gpio125_cfg_idle &gpio037_cfg_idle &gpio088_cfg_idle &gpio040_cfg_idle>;
		vsp-vsn-voltage = <15>;
		fpga_flag = <0>;
		status = "disabled";
	};

	panel_lcd_jdi_eR63450 {
		#address-cells = <2>;
		#size-cells = <2>;
		compatible = "hisilicon,mipi_jdi_eR63450";
		//2:PWM,  4:BLPWM,  8:MIPI
		lcd-bl-type = <4>;
		//8:PANEL_MIPI_VIDEO,  16:PANEL_MIPI_CMD
		lcd-display-type = <8>;
		//5:IFBC_TYPE_RSP3X
		lcd-ifbc-type = <5>;
		//gpio_lcd_p5v5_enable, gpio_lcd_n5v5_enable, gpio_lcd_bl_enable, gpio_lcd_reset,  gpio_lcd_te0
		gpios = <&gpio15 5 0>, <&gpio4 5 0>,  <&gpio11 0 0>,  <&gpio5 0 0>, <&gpio2 7 0>;
		//gpio_lcd_p5v5_enable, gpio_lcd_n5v5_enable, gpio_lcd_bl_enable, gpio_lcd_reset,  gpio_lcd_te0, ID0, tp_reset
		gpio_nums = <125 37 88 40 23 33 65>;
		lcdio-vcc-supply = <&ldo4>;
		lcdanalog-vcc-supply = <&ldo17>;
		pinctrl-names = "default", "idle";
		pinctrl-0 = <&gpio125_pmx_func &gpio037_pmx_func &gpio088_pmx_func &gpio040_pmx_func &gpio125_cfg_func &gpio037_cfg_func &gpio088_cfg_func &gpio040_cfg_func>;
		pinctrl-1 = <&gpio125_pmx_idle &gpio037_pmx_idle &gpio088_pmx_idle &gpio040_pmx_idle &gpio125_cfg_idle &gpio037_cfg_idle &gpio088_cfg_idle &gpio040_cfg_idle>;
		vsp-vsn-voltage = <15>;
		fpga_flag = <0>;
		status = "disabled";
	};

	panel_lcd_lg_TD4322_6P0_chicago {
		#address-cells = <2>;
		#size-cells = <2>;
		compatible = "hisilicon,mipi_lg_TD4322_6P0_chicago";
		//2:PWM,  4:BLPWM,  8:MIPI
		lcd-bl-type = <4>;
		//8:PANEL_MIPI_VIDEO,  16:PANEL_MIPI_CMD ,32:PANEL_DUAL_MIPI_VIDEO, 64:PANEL_DUAL_MIPI_CMD
		lcd-display-type = <16>;
		//0:IFBC_TYPE_NONE 7:IFBC_TYPE_VESA3X_SINGLE 9:IFBC_TYPE_VESA3X_DUAL
		lcd-ifbc-type = <0>;
		//gpio_lcd_p5v5_enable, gpio_lcd_n5v5_enable, gpio_lcd_bl_enable, gpio_lcd_reset,  gpio_lcd_te0
		gpios = <&gpio15 5 0>, <&gpio4 5 0>,  <&gpio11 0 0>,  <&gpio5 0 0>, <&gpio2 7 0>;
		//gpio_lcd_p5v5_enable, gpio_lcd_n5v5_enable, gpio_lcd_bl_enable, gpio_lcd_reset,  gpio_lcd_te0, ID0, tp_reset
		gpio_nums = <125 37 88 40 23 33 65>;
		lcdio-vcc-supply = <&ldo4>;
		lcdanalog-vcc-supply = <&ldo17>;
		pinctrl-names = "default", "idle";
		pinctrl-0 = <&gpio125_pmx_func &gpio037_pmx_func &gpio088_pmx_func &gpio040_pmx_func &gpio125_cfg_func &gpio037_cfg_func &gpio088_cfg_func &gpio040_cfg_func>;
		pinctrl-1 = <&gpio125_pmx_idle &gpio037_pmx_idle &gpio088_pmx_idle &gpio040_pmx_idle &gpio125_cfg_idle &gpio037_cfg_idle &gpio088_cfg_idle &gpio040_cfg_idle>;
		vsp-vsn-voltage = <15>;
		fpga_flag = <0>;
		status = "disabled";
	};

	panel_lcd_external_jdi_NT35695 {
		#address-cells = <2>;
		#size-cells = <2>;
		compatible = "hisilicon,external_mipi_jdi_NT35695";
		//2:PWM,  4:BLPWM,  8:MIPI
		lcd-bl-type = <8>;
		//8:PANEL_MIPI_VIDEO,  16:PANEL_MIPI_CMD
		lcd-display-type = <8>;
		//0:IFBC_TYPE_NONE 7:IFBC_TYPE_VESA3X_SINGLE 9:IFBC_TYPE_VESA3X_DUAL
		lcd-ifbc-type = <0>;
		//gpio_lcd_p5v5_enable, gpio_lcd_n5v5_enable, gpio_lcd_bl_enable, gpio_lcd_reset
		gpio_nums = <256 257 260 262>;
		lcdio-vcc-supply = <&ldo4>;
		//lcdanalog-vcc-supply = <&ldo17>;
		//pinctrl-names = "default", "idle";
		//pinctrl-0 = <&gpio021_pmx_func &gpio021_cfg_func &gpio009_cfg_func &gpio010_cfg_func &gpio015_cfg_func &gpio020_cfg_func>;
		//pinctrl-1 = <&gpio021_pmx_idle &gpio021_cfg_idle &gpio009_cfg_idle &gpio010_cfg_idle &gpio015_cfg_idle &gpio020_cfg_idle>;
		fpga_flag = <0>;
		status = "disabled";

	};

	panel_mipi_lcd_external {
		#address-cells = <2>;
		#size-cells = <2>;
		compatible = "hisilicon,mipi_lcd_external_panel";
		//2:PWM,  4:BLPWM,  8:MIPI
		lcd-bl-type = <4>;
		//8:PANEL_MIPI_VIDEO,  16:PANEL_MIPI_CMD
		lcd-display-type = <16>;
		//0:IFBC_TYPE_NONE
		lcd-ifbc-type = <0>;
		//gpio_lcd_vcc1v8, gpio_lcd_p5v5_enable, gpio_lcd_n5v5_enable, gpio_lcd_reset, gpio_lcd_bl_enable
		gpios = <&gpio6 3 0>, <&gpio9 3 0>,  <&gpio8 1 0>, <&gpio7 7 0>, <&gpio8 0 0>;
		gpio_nums = <51 75 65 63 64>;
		//lcdio-vcc-supply = <&ldo4>;
		//lcdanalog-vcc-supply = <&ldo17>;
		//pinctrl-names = "default", "idle";
		//pinctrl-0 = <&gpio021_pmx_func &gpio021_cfg_func &gpio009_cfg_func &gpio010_cfg_func &gpio015_cfg_func &gpio020_cfg_func>;
		//pinctrl-1 = <&gpio021_pmx_idle &gpio021_cfg_idle &gpio009_cfg_idle &gpio010_cfg_idle &gpio015_cfg_idle &gpio020_cfg_idle>;
		fpga_flag = <0>;
		status = "disabled";
	};
	panel_hdmi_fake {
		#address-cells = <2>;
		#size-cells = <2>;
		compatible = "hisilicon,hdmi_fake_panel";
		fake_hdmi = <1>;
		status = "ok";
	};

	/* display end */
bluetooth_power: bluetooth_power{
                status = "ok";
                huawei,bt_en = <126>;
                huawei,no_vio_switch = <1>;
        };

        bluetooth_sleep: bluetooth_sleep{
                status = "ok";
                huawei,host_wake_bt = <44>;
                huawei,bt_wake_host = <147>;
        };
	/* audio device beg */
	codec_controller: codec_controller@e82b9000 {
		gpios = <&gpio26 1 0>; /* GPIO_209 */
		gpio_reset = <45>; /* GPIO_5_5*/
		gpio_codec_ssi = <201>;
		gpio_codec_ssi_func = <1>;
		gpio_ssi_mux = <16>; /* Chicago FPGA only */
		pm_runtime_support;
		platform-type = "UDP";
		status = "ok";

		hi64xx_irq: hi64xx_irq@0 {
			status = "ok";

			hi6402_codec: hi6402_codec@0{
				hisilicon,mic_num = <2>;
				status = "disabled";
			};

			hi6403_codec: hi6403_codec@0{
				hisilicon,mic_num = <2>;
				gpio_pd_enable;
				status = "disabled";
			};

			hi6403es_codec: hi6403es_codec@0{
				hisilicon,mic_num = <2>;
				gpio_pd_enable;
				status = "disabled";
			};

			gpio29: gpio@0{
				status = "disabled";
			};

			gpio30: gpio@1{
				status = "disabled";
			};

			gpio31: gpio@2{
				status = "disabled";
			};

			gpio32: gpio@3{
				status = "disabled";
			};

			pmx4: hi6402_pinctrl {
				status = "disabled";
			};
		};
	};

	codecssi@0xe82b9000 {
		/* ssi pinctrl */
		pinctrl-names = "default", "idle";
		pinctrl-0 = <&gpio201_cfg_func &gpio201_pmx_func>;
		pinctrl-1 = <&gpio201_cfg_idle &gpio201_pmx_idle>;
		status = "disabled";
	};

	sound_hi6403es {
		compatible = "hisilicon,hi3xxx-hi6403es";
		status = "disabled";
	};

	sound_hi6403 {
		compatible = "hisilicon,hi3xxx-hi6403";
		status = "disabled";
	};

	hi6210_hifi {
		compatible = "hi6210-hifi";
		status = "ok";
	};

	asp_irq: asp_irq@E804E000{
		compatible = "hisilicon,hi3630-asp-irq";
		reg = <0x0 0xe804e000 0x0 0xa000>;
		#interrupt-cells = <0x2>;
		asp-irq-supply = <&asp>;
		interrupt-controller;
		interrupts = <0x0 0x88 0x4>;
		interrupt-names = "asp_irq";

		asp_common@0 {
			compatible = "hisilicon,hi3630-asp-common";
		};

		asp_srcup_normal@0 {
			compatible = "hisilicon,hi3630-srcup-normal";
			asp-srcup-normal-supply = <&asp>;
			interrupt-parent = <&asp_irq>;
			interrupts = <0x1 0x0>;
			interrupt-names = "asp_srcup_normal";
		};

		asp_srcup_dsp@0 {
			compatible = "hisilicon,hi3630-srcup-dsp";
		};

		asp_srcdown@0 {
			compatible = "hisilicon,hi3630-srcdown";
			interrupt-parent = <&asp_irq>;
		};

		asp_hdmi@0 {
			compatible = "hisilicon,hi3630-pcm-hdmi";
			interrupt-parent = <&asp_irq>;
			interrupts = <0x0 0x0>;
			interrupt-names = "asp_irq_hdmi";
		};
	};
	slimbusmisc@0xe8050000 {
		compatible = "candance,slimbus";
		reg = <0x0 0xe8050000 0x0 0xb00>,
			<0x0 0xe804e000 0x0 0xa000>,
			<0x0 0xfff0a000 0x0 0x1000>;
		interrupts = <0x0 0x96 0x4>;
		interrupt-names = "asp_irq_slimbus";
		slimbus-reg-supply = <&asp>;
		pinctrl-names = "default", "idle";
		pinctrl-0 = <&gpio189_pmx_func
				&gpio190_pmx_func
				&gpio189_cfg_func
				&gpio190_cfg_func>;
		pinctrl-1 = <&gpio189_pmx_idle
				&gpio190_pmx_idle
				&gpio189_cfg_idle
				&gpio190_cfg_idle>;
		slimbus-ssi-sel = "slimbus";
		asp_power_state_offset = <0x06c>;
		platform-type   = "UDP";
		codec-type	= "slimbus-6403es";
		clk_asp_subsys = <533000>;
		slimbusclk_io_driver = <0xa0>;
		slimbusdata_io_driver = <0xa3>;
		slimbus_dynamic_freq = "true";
		pm_runtime_support;
		status = "ok";
	};
	slimbus_dai@0 {
		compatible = "hisilicon,slimbus-dai";
		status = "ok";
	};

	sio@E804F000 {
		compatible = "hisilicon,hi3630-sio";
		reg = <0x0 0xE804F000 0x0 0x400>;
		sio-audio-supply = <&asp>;
		/* wbd
		pinctrl-names = "default", "idle";
		pinctrl-0 = <&gpio183_pmx_func
				    &gpio184_pmx_func
				    &gpio185_pmx_func
				    &gpio186_pmx_func
				    &gpio183_cfg_func
				    &gpio184_cfg_func
				    &gpio185_cfg_func
				     &gpio186_cfg_func>;
		pinctrl-1 = <&gpio183_pmx_idle
				    &gpio184_pmx_idle
				    &gpio185_pmx_idle
				    &gpio186_pmx_idle
				    &gpio183_cfg_idle
				    &gpio184_cfg_idle
				    &gpio185_cfg_idle
				    &gpio186_cfg_idle>;
		*/
		status = "disabled";
	};

	sio@E804F400 {
		compatible = "hisilicon,hi3630-sio";
		reg = <0x0 0xE804F400 0x0 0x400>;
		sio-voice-supply = <&asp>;
		/* wbd
		pinctrl-names = "default", "idle";
		pinctrl-0 = <&gpio043_pmx_func
				     &gpio044_pmx_func
				     &gpio045_pmx_func
				     &gpio046_pmx_func
				     &gpio043_cfg_func
				     &gpio044_cfg_func
				     &gpio045_cfg_func
				     &gpio046_cfg_func>;
			pinctrl-1 = <&gpio043_pmx_idle
				     &gpio044_pmx_idle
				     &gpio045_pmx_idle
				     &gpio046_pmx_idle
				     &gpio043_cfg_idle
				     &gpio044_cfg_idle
				     &gpio045_cfg_idle
				     &gpio046_cfg_idle>;
		*/
		status = "disabled";
	};

	sio@E804F800 {
		compatible = "hisilicon,hi3630-sio";
		reg = <0x0 0xE804F800 0x0 0x400>;
		status = "disabled";
	};

	sio@E804FC00 {
		compatible = "hisilicon,hi3630-sio";
		reg = <0x0 0xE804FC00 0x0 0x400>;
		status = "disabled";
	};

	asp_dmac@E804B000 {
		compatible = "hisilicon,hi3xxx-pcm-asp-dma";
		reg = <0x0 0xe804b000 0x0 0x1000>;
		asp-dmac-supply = <&asp>;
		status = "ok";
	};

	st_asp_dmac@E804B000 {
		compatible = "hisilicon,soundtrigger_dma_drv";
		reg = <0x0 0xe804b000 0x0 0x1000>;
		asp-dmac-supply = <&asp>;
		status = "ok";
	};

	hi64xx_asp_dmac@E804B000 {
		compatible = "hisilicon,hi64xx-asp-dma";
		reg = <0x0 0xe804b000 0x0 0x1000>;
		asp-dmac-supply = <&asp>;
		interrupts = <0 216 4>;
		interrupt-names = "asp_dma_irq";
		status = "ok";
	};

        hifidsp {
                compatible = "hisilicon,k3hifidsp";
                status = "ok";
                platform-type = "ASIC";
        };

	sochifi_watchdog {
		compatible = "hisilicon,sochifi-watchdog";
		interrupts = <0 213 4>;
		status = "ok";
	};

	audio_hw_config {
		product_name = "hi3660";
		spk_pa_name = "max98925";
		cust_name = "audio_custom";
		soc_name = "hi363x";
		codec_name = "hi6403";
		codec_dsp_algo = "maxim|mad|anc";
		modem_sio_master = "false";
		ear_pa_name = "none";
		status = "ok";
		audio_capability {
			bwe_ui_support = "false";
			bwe_support = "true";
			swb_support = "true";
			wnr_support = "false";
			nv_evs_support = "true";
			lvm_support = "false";
			dhf_support = "false";
			voice_anc_support = "true";
			dual_smartpa_support = "false";
			spk_rcv_stereo_support = "false";
			earphone_multi_eq_support = "false";
			vdr_ui_support = "false";
			/*
				sound trigger feature.
				false: this product doesn't support soundtrigger feature.
				2.0: this product supports the twice wakeup feature.
			*/
			soundtrigger_version = "2.0";
		};
	};

	hw_soundtrigger_event: hw_soundtrigger_event{
		status = "ok";
	};
	/* audio device end */

	/* UFS */
	ufs: ufs@FF3b0000 {
		ufs-kirin-use-rate-B;
		ufs-kirin-broken-fastauto;
		/*ufs-kirin-use-one-line;*/
		ufs-kirin-use-HS-GEAR3;
		/*ufs-kirin-use-HS-GEAR2;*/
		/*ufs-kirin-use-HS-GEAR1;*/
		ufs-kirin-unipro-termination;
		/*ufs-kirin-unipro-scrambing;*/
		/*ufs-kirin-use-auto-H8*/
		ufs-kirin-broken-clk-gate-bypass;
	};

	/* eMMC0 */
	sdhci0: sdhci@FF3FB000 {
		clk-ahb = <115000000>;
		clk-xin = <192000000>;
		vmmc-supply = <&ldo15>;
		caps2-mmc-hs400-1_8v;/*caps2-mmc-hs400-1_8v, caps2-mmc-hs200-1_8v, caps2-mmc-ddr50-1_8v*/
		/*caps2-mmc-packed-command;*/
		keep-power-in-suspend;
		/*caps2-mmc-poweroff-notify;*/
		/*caps2-mmc-enhanced_strobe-ctrl;*/
		/*caps2-mmc-cache_flush_barrier-ctrl;*/
		caps2-mmc-bkops_auto-ctrl;
		caps2-mmc-cmd-queue;
	};

	/* SD */
	dwmmc1: dwmmc1@FF37F000 {
		vmmc-supply = <&ldo16>;
		vqmmc-supply = <&ldo9>;
		cd-vol = <0>;
		cd-gpio = <&gpio24 0 0>;
		status = "ok";
	};

	/* wifi */
	dwmmc2: dwmmc2@FF3FF000 {
		sdio_support_uhs;
		status = "ok";
	};

	hisi_usb@ff200000 {
		usbldo10-supply = <&ldo10>;
	};

	touchscreen {
		bus_id = <7>;
		product = "next";
		has_virtualkey = <0>;
		fpga_flag = <0>;
		synaptics: touchscreen@70 {
			algo_id = <1>;
			ic_type = <2>;
			vci_gpio_type = <0>;
			vci_regulator_type = <1>;
			vddio_gpio_type = <0>;
			vddio_regulator_type = <1>;
			reset_gpio = <&gpio8 1 0>;
			attn_gpio = <&gpio26 4 0>;
			pinctrl-names = "default", "idle";
			pinctrl-0 = <&gpio065_cfg_func>;
			pinctrl-1 = <&gpio065_cfg_idle>;
			synaptics-vdd-supply = <&ldo17>;
			synaptics-io-supply = <&ldo4>;
			irq_config = <0>;
			x_max = <1080>;
			y_max = <1920>;
			x_max_mt = <1080>;
			y_max_mt = <1920>;
			raw_data_limit = "4600", /*rawdata-max*/
					 "2300", /*rawdata-min*/
					 "20", /*deltadata-max*/
					 "-20", /*deltadata-min*/
					 "390", /*rx-to-rx-diff-max*/
					 "-390", /*rx-to-rx-diff-min*/
					 "390", /*tx-to-tx-diff-max*/
					 "-390";/*tx-to-tx-diff-min*/

			NEXT11080 {
				compatible = "synaptics-NEXT11080";	//jdi S3320B
				holster_switch_addr = <0x0419>;
				holster_switch_bit = <0>;
				glove_switch_addr = <0x001F>;
				glove_switch_bit = <0>;
				roi_supported = <1>;
				roi_control_addr = <0x041B>;
				roi_control_bit = <0>;
				roi_data_addr = <0x0418>;
			};

			NEXT18100 {
				compatible = "synaptics-NEXT18100";
				ic_type = <3>;
				report_rate_test = <0>;
				supported_func_indicater = <0x01>;
				raw_data_limit = "450", "50", "40", "-40", "390", "-390", "390", "-390";
				holster_switch_addr = <0x001C>;
				holster_switch_bit = <1>;
				glove_switch_addr = <0x001C>;
				glove_switch_bit = <0>;
				roi_supported = <1>;
				roi_control_addr = <0x043A>;
				roi_control_bit = <0>;
				roi_data_addr = <0x0418>;
			};
		};
	};

	sensorhub_status{
		compatible = "huawei,sensorhub_status";
		status= "ok";
	};

	sensorhub_nmi{
		compatible = "huawei,sensorhub_nmi";
		nmi_reg=<0x588>;
	};

    sensorhub_dump{
        compatible = "huawei,sensorhub_dump";
        enable = <1>;
        ext_regions = <0>;
        extend_region_size = <0x80000>;
        dump_dir = "/data/log/sensorhub-log/";
        dump_fs = "/data/lost+found";
    };

	gps_power: gps_power{
		status = "ok";
		huawei,gps_en = <&gpio4 4 0>;
		huawei,gps_hostwake = <&gpio26 2 0>;
		pinctrl-0 = <&gpio012_pmx_func &gpio012_cfg_func>;
		pinctrl-1 = <&gpio012_pmx_idle &gpio012_cfg_idle>;
		huawei,gps_refclk = <12>;
		huawei,mcu_req = <&gpio21 1 0>;
		huawei,mcu_req_rsp = <&gpio21 0 0>;
		broadcom_config,ic_type="bcm4774";
		broadcom_config,tty_port="ttyAMA3";
	};
	sensorhub{
		#address-cells=<1>;
		#size-cells=<0>;
		als_sensor:light{
			als1{
				compatible="huawei,rohm_bh1745";
				reg=<0x38>;
				chip_id_value=<0xE0>;
				file_id=<38>;
				poll_interval=<350>;
				gpio_int1=<&gpio26 6 0>;
				als_phone_type = <11>;
				als_phone_version = <10>;
				als_extend_data = <0 0 0 0 0 0 0 0 0 0 0 0>;
				status = "disable";
			};
			als2{
				compatible="huawei,avago_apds9251";
				bus_number = <0x0>;
				reg=<0x52>;
				chip_id_register = <0x06>;
				chip_id_value = <0xB2>;
				file_id = <41>;
				sensor_list_info_id = <0x19>;
				sensor_type = "als";
				poll_interval = <120>;
				threshold_value = <0x1>;
				GA1 = <0x1046>;
				GA2 = <0xf3c>;
				GA3 = <0x1194>;
				tp_color = <0x0>;
				again = <0x1>;
				gpio_int1 = <0x38 0x6 0x0>;
				atime = <0xdb>;
				init_time = <0x96>;
				status = "disable";
				als_phone_type = <11>;
				als_phone_version = <11>;
				als_extend_data = <0x0 0x0 0x0 0x0 0x0 0x0 0x0 0x0 0x0 0x0 0x0 0x0>;
			};
		};

		ps_sensor:proximity{
			ps1{
				compatible="huawei,txc-pa224";
				reg=<0x1e>;
				chip_id_register=<0x7F>;
				chip_id_value=<0x11>;
				file_id=<39>;
				min_proximity_value=<220>;
				pwindows_value=<14>;
				pwave_value=<12>;
				threshold_value=<25>;
				gpio_int1=<&gpio27 1 0>;
				poll_interval = <30>;
				status = "disable";
			};

		};
		acc_sensor:gsensor{
			acc1{
				compatible="huawei,bosch-bmi160";
				reg=<0x68>;
				chip_id_register=<0x0>;
				chip_id_value=<0xd1>;
				file_id=<33>;
				axis_map_x=<1>;
				axis_map_y=<0>;
				axis_map_z=<2>;
				negate_x=<1>;
				negate_y=<1>;
				negate_z=<1>;
				offset_x=<0>;
				offset_y=<0>;
				offset_z=<0>;
				sensitivity_x=<1>;
				sensitivity_y=<1>;
				sensitivity_z=<1>;
				gpio_int2=<&gpio24 4 0>;
				gpio_int2_sh=<251>;
				calibrate_style=<0>;
				sensorlist_name="accelerometer-bmi160";
				vendor="bosch";
				status = "ok";
			};
			acc2{
				compatible="huawei,st-lsm6ds3";
				bus_number=<0>;
				reg=<0x6a>;
				chip_id_register=<0x0f>;
				chip_id_value=<0x69>;
				file_id=<34>;
				sensor_list_info_id=<0>;
				sensor_type="acc";
				/*sensor-vdd-supply = <&ldo24>;*/
				axis_map_x=<0>;
				axis_map_y=<1>;
				axis_map_z=<2>;
				negate_x=<0>;
				negate_y=<1>;
				negate_z=<1>;
				offset_x=<0>;
				offset_y=<0>;
				offset_z=<0>;
				sensitivity_x=<1>;
				sensitivity_y=<1>;
				sensitivity_z=<1>;
				poll_interval=<10>;
				gpio_int1=<&gpio26 0 0>;
				gpio_int2=<&gpio24 4 0>;
				gpio_int2_sh=<251>;
				calibrate_style=<0>;
				sensorlist_name="accelerometer-lsm6ds3";
				vendor="st";
				status = "ok";
			};
			acc3{
				compatible ="huawei,st-lsm6dsm";
				bus_number =<0>;
				reg =<0x6a>;
				chip_id_register =<0x0f>;
				chip_id_value =<0x6a>;
				file_id =<34>;
				sensor_list_info_id =<0>;
				sensor_type ="acc";
				axis_map_x =<1>;
				axis_map_y =<0>;
				axis_map_z =<2>;
				negate_x =<0>;
				negate_y =<1>;
				negate_z =<0>;
				offset_x =<0>;
				offset_y =<0>;
				offset_z =<0>;
				sensitivity_x =<1>;
				sensitivity_y =<1>;
				sensitivity_z =<1>;
				poll_interval =<10>;
				gpio_int1 =<&gpio26 0 0>;
				gpio_int2 =<&gpio24 4 0>;
				gpio_int2_sh=<251>;
				calibrate_style =<0>;
				sensorlist_name="accelerometer-lsm6dsm";
				vendor="st";
				status = "ok";
			};
			acc4{
				compatible ="huawei,invensense-icm20690";
				bus_number =<0>;
				reg =<0x68>;
				chip_id_register =<0x75>;
				chip_id_value =<0x20>;
				file_id =<53>;
				sensor_list_info_id =<0>;
				sensor_type ="acc";
				axis_map_x =<1>;
				axis_map_y =<0>;
				axis_map_z =<2>;
				negate_x =<0>;
				negate_y =<1>;
				negate_z =<0>;
				offset_x =<0>;
				offset_y =<0>;
				offset_z =<0>;
				sensitivity_x =<1>;
				sensitivity_y =<1>;
				sensitivity_z =<1>;
				poll_interval =<10>;
				gpio_int1 =<&gpio26 0 0>;
				gpio_int2 =<&gpio24 4 0>;
				gpio_int2_sh=<251>;
				calibrate_style =<0>;
				sensorlist_name="accelerometer-icm20690";
				vendor="invensense";
				status = "ok";
			};
		};

		gyro_sensor:gyroscope{
			gyro1{
				compatible ="huawei,bosch-bmi160";
				reg=<0x68>;
				chip_id_register=<0x0>;
				chip_id_value=<0xd1>;
				file_id=<35>;
				axis_map_x=<1>;
				axis_map_y=<0>;
				axis_map_z=<2>;
				negate_x=<1>;
				negate_y=<1>;
				negate_z=<1>;
				gpio_int2=<&gpio24 4 0>;
				gpio_int2_sh=<251>;
				sensorlist_name="gyroscope-bmi160";
				vendor="bosch";
				status = "ok";
			};
			gyro2{
				compatible ="huawei,st-lsm6ds3";
				bus_number=<0>;
				reg=<0x6a>;
				chip_id_register=<0x0f>;
				chip_id_value=<0x69>;
				file_id=<36>;
				sensor_list_info_id=<5>;
				sensor_type="gyro";
				/*sensor-vdd-supply = <&ldo24>;*/
				axis_map_x=<0>;
				axis_map_y=<1>;
				axis_map_z=<2>;
				negate_x=<0>;
				negate_y=<1>;
				negate_z=<1>;
				poll_interval=<10>;
				gpio_int1=<&gpio26 2 0>;
				gpio_int2=<&gpio24 4 0>;
				gpio_int2_sh=<251>;
				sensorlist_name="gyroscope-lsm6ds3";
				vendor="st";
				status = "ok";
			};
			gyro3{
				compatible ="huawei,st-lsm6dsm";
				bus_number =<0>;
				reg =<0x6a>;
				chip_id_register =<0x0f>;
				chip_id_value =<0x6a>;
				file_id =<36>;
				sensor_list_info_id =<5>;
				sensor_type ="gyro";
				axis_map_x =<1>;
				axis_map_y =<0>;
				axis_map_z =<2>;
				negate_x =<0>;
				negate_y =<1>;
				negate_z =<0>;
				poll_interval =<10>;
				gpio_int1 =<&gpio26 2 0>;
				gpio_int2=<&gpio24 4 0>;
				gpio_int2_sh=<251>;
				sensorlist_name="gyroscope-lsm6dsm";
				vendor="st";
				status = "ok";
			};
			gyro4{
				compatible ="huawei,inv-icm20690";
				bus_number =<0>;
				reg =<0x68>;
				chip_id_register =<0x75>;
				chip_id_value =<0x20>;
				file_id =<54>;
				sensor_list_info_id =<5>;
				sensor_type ="gyro";
				axis_map_x =<1>;
				axis_map_y =<0>;
				axis_map_z =<2>;
				negate_x =<0>;
				negate_y =<1>;
				negate_z =<0>;
				poll_interval =<10>;
				gpio_int1 =<&gpio26 2 0>;
				gpio_int2=<&gpio24 4 0>;
				gpio_int2_sh=<251>;
				sensorlist_name="gyroscope-icm20690";
				vendor="invensense";
				status = "ok";
			};
		};
		mag_sensor:compass{
			mag1{
				compatible="huawei,akm-akm09911";
				bus_number=<0>;
				reg=<0x0D>;
				chip_id_register=<0x00>;
				chip_id_value=<0x48>;
				file_id=<37>;
				sensor_list_info_id=<1>;
				sensor_type="mag";
				/*sensor-vdd-supply = <&ldo24>;*/
				outbit=<0>;
				calibrate_method=<2>;
				axis_map_x=<1>;
				axis_map_y=<0>;
				axis_map_z=<2>;
				negate_x=<1>;
				negate_y=<0>;
				negate_z=<0>;
				poll_interval=<10>;
				gpio_int1=<&gpio0 0 0>;
				gpio_reset=<&gpio0 0 0>;
				softiron_parameter = <13 39 19 255 59 00 19 255 59 41 221 255 59 00 221 255 102 42 0 0 0 0 0 0 0 0 0>;
				sensorlist_name="mag-akm09911";
				vendor="akm";
				status = "ok";
			};
		};
		airpress_sensor:airpress{
			airpress1{
				compatible="huawei,rohm_bm1383";
				bus_number=<0>;
				reg=<0x5D>;
				chip_id_register=<0x10>;
				chip_id_value=<0x31>;
				file_id=<40>;
				sensor_list_info_id=<0x9>;
				sensor_type="airpress";
				poll_interval = <500>;
				sensorlist_name="airpress-bm1383";
				vendor="rohm";
				status = "ok";
			};
		};
	};

	sensorhub_ext_config:sensorhub_ex{
		compatible = "huawei,sensorhub";
		akm_need_current = "no";
		invensense_exist = "no";
		isensor_version = "no";
		hifi_support = <0>;
		adapt_sensor_list_id = <2 6 7 8 11 12 13 14 15 16 17 18 21 22 23>;
		adapt_file_id = <9>;
	};

	sensorhub_io_power{
		compatible = "huawei,sensorhub_io";
		sensor-io-supply = <&ldo24>;
		status="ok";
	};

	hall {
		compatible = "huawei,hall_sensor,ak8789";
		status = "ok";
		huawei,hall_0{
			huawei,single-n-pole = <&gpio23 2 0>;
			huawei,type = <0x01>;
			huawei,default-state = "on";
		};
	};
	/*
		device check : the 0 means that it don't need to check;
			the 1 means that it check at board check and running test;
			the 2 means that it check at running test
	*/
	devcheck: devcheck {
		touch_panel = <2>;
		compass = <1>;
		g_sensor = <1>;
		gyroscope = <1>;
		nfc = <1>;
		dc_dc = <1>;
		tps = <1>;
		l_sensor = <2>;
		charge = <1>;
		usb_switch = <1>;
		wifi = <1>;
		bt = <1>;
		gps = <1>;
		antenna_ctl = <0>;
		airpress = <1>;
		vibrator_lra = <1>;
		status = "ok";
	};

	huawei,hisi_isp150 {
		hisi,is_fpga = <0>;
                pinctrl-names = "default", "idle";
                pinctrl-0 = <
                 &gpio027_pmx_func
                 &gpio028_pmx_func
                 &gpio029_pmx_func
                 &gpio030_pmx_func
                 &gpio031_pmx_func
                 &gpio032_pmx_func
                 &gpio034_pmx_func
                 &gpio051_pmx_func
                 &gpio052_pmx_func
                 &gpio075_pmx_func
                 &gpio078_pmx_func
                 &gpio146_pmx_func
                 &gpio173_pmx_func
                 &gpio027_cfg_func
                 &gpio028_cfg_func
                 &gpio029_cfg_func
                 &gpio030_cfg_func
                 &gpio031_cfg_func
                 &gpio032_cfg_func
                 &gpio034_cfg_func
                 &gpio051_cfg_func
                 &gpio052_cfg_func
                 &gpio075_cfg_func
                 &gpio078_cfg_func
                 &gpio146_cfg_func
                 &gpio173_cfg_func
                 &gpio177_cfg_func
                 >;
                pinctrl-1 = <
                 &gpio027_pmx_idle
                 &gpio028_pmx_idle
                 &gpio029_pmx_idle
                 &gpio030_pmx_idle
                 &gpio031_pmx_idle
                 &gpio032_pmx_idle
                 &gpio034_pmx_idle
                 &gpio051_pmx_idle
                 &gpio052_pmx_idle
                 &gpio075_pmx_idle
                 &gpio078_pmx_idle
                 &gpio146_pmx_idle
                 &gpio173_pmx_idle
                 &gpio027_cfg_idle
                 &gpio028_cfg_idle
                 &gpio029_cfg_idle
                 &gpio030_cfg_idle
                 &gpio031_cfg_idle
                 &gpio032_cfg_idle
                 &gpio034_cfg_idle
                 &gpio051_cfg_idle
                 &gpio052_cfg_idle
                 &gpio075_cfg_idle
                 &gpio078_cfg_idle
                 &gpio146_cfg_idle
                 &gpio173_cfg_idle
                 &gpio177_cfg_idle
                 >;
                status = "ok";
	};

	hisi,hisi_camera {
		hisi,is_fpga = <0>;

	};
	huawei,imx286hybird{
		compatible = "huawei,imx286hybird_udp";
		huawei,sensor_name = "IMX286HYBIRD";
		huawei,sensor_index = <0>;
		huawei,is_fpga = <0>;
		huawei,pd_valid = <1>;
		huawei,reset_valid = <1>;
		huawei,vcmpd_valid = <0>;
		huawei,csi_index = <0 2>;
		huawei,i2c_index = <0 2>;
		clocks = <&clk_gate_isp_snclk0 &clk_gate_isp_snclk2>;
		clock-names = "clk_isp_snclk0", "clk_isp_snclk2";
		huawei,mclk = <24000000>;
		gpios = <&gpio6 4 0 &gpio33 8 0 &gpio6 3 0>;
		huawei,gpio-ctrl-types = "reset", "reset2",  "ldo_en";
		module_type = <0>;/*bit0=enable ,other bits=type*/
		status = "ok";
	};

	huawei,imx179 {
		huawei,is_fpga = <0>;
		huawei,csi_index = <1>;
		huawei,i2c_index = <1>;
		clocks = <&clk_gate_isp_snclk1>;
		clock-names = "clk_isp_snclk1";
		huawei,mclk = <24000000>;

		vcm-supply = <&ldo25>;
		avdd2-supply = <&ldo19>;
		dvdd2-supply = <&ldo20>;
		avdd-supply = <&ldo13>;
		dvdd-supply = <&ldo32>;
		huawei,ldo-names = "vcm", "avdd2", "dvdd2", "avdd", "dvdd";

		gpios = <&gpio6 4 0 &gpio6 3 0 &gpio18 2 0 &gpio2 6 0>;
		huawei,gpio-ctrl-types = "suspend", "ldo_en", "reset", "vcm_pwdn";
		status = "ok";
	};

	huawei,ov8865 {
		compatible = "huawei,ov8865";
		huawei,sensor_name = "OV8865";
		huawei,is_fpga = <0>;
		huawei,pd_valid = <1>;
		huawei,sensor_index = <1>;
		huawei,csi_index = <1>;
		huawei,i2c_index = <1>;
		huawei,reset_valid = <1>;
		clock-names = "clk_isp_snclk1";
		clocks = <&clk_gate_isp_snclk1>;
		huawei,mclk = <24000000>;

		huawei,vcmpd_valid = <0>;
		vcm-supply = <&ldo25>;
		avdd2-supply = <&ldo19>;
		dvdd2-supply = <&ldo20>;
		avdd-supply = <&ldo13>;
		dvdd-supply = <&ldo32>;
		huawei,ldo-names = "vcm", "avdd2", "dvdd2", "avdd", "dvdd";

		gpios = <&gpio6 4 0 &gpio6 3 0 &gpio18 2 0 &gpio2 6 0>;
		huawei,gpio-ctrl-types = "suspend", "ldo_en", "reset", "vcm_pwdn";
		status = "ok";
	};

    huawei,ov2281 {
        compatible = "huawei,ov2281";
        huawei,sensor_name = "OV2281";
        huawei,is_fpga = <0>;
        huawei,csi_index = <2>;
        huawei,i2c_index = <2>;
        huawei,sensor_index = <8>;
        huawei,reset_valid = <1>;
        clocks = <&clk_gate_isp_snclk2>;
        clock-names = "clk_isp_snclk2";
        huawei,mclk = <24000000>;
        avdd-supply = <&ldo19>;
        /* dvdd-supply = <&ldo32>; */
        /* huawei,ldo-names = "avdd", "dvdd"; */
        huawei,ldo-names = "avdd";

        gpios = <&gpio18 2 0 &gpio6 3 0 &gpio33 8 0>;
        huawei,gpio-ctrl-types = "suspend", "ldo_en", "reset";
        status = "ok";
    };

	huawei,imx286dual{
		compatible = "huawei,imx286dual_udp";
		huawei,sensor_name = "IMX286DUAL";
		huawei,sensor_index = <0>;
		huawei,is_fpga = <0>;
		huawei,pd_valid = <1>;
		huawei,reset_valid = <1>;
		huawei,vcmpd_valid = <0>;
		huawei,csi_index = <0 2>;
		huawei,i2c_index = <0 2>;
		clocks = <&clk_gate_isp_snclk0 &clk_gate_isp_snclk2>;
		clock-names = "clk_isp_snclk0", "clk_isp_snclk2";
		huawei,mclk = <24000000>;
		gpios = <&gpio6 4 0 &gpio33 8 0 &gpio6 3 0>;
		huawei,gpio-ctrl-types = "reset", "reset2",  "ldo_en";
		module_type = <0>;/*bit0=enable ,other bits=type*/
		status = "ok";
	};

	huawei,imx214 {
		huawei,is_fpga = <1>;
		gpios = <&gpio11 3 0 &gpio11 1 0 &gpio10 7 0 &gpio11 0 0 &gpio10 6 0 &gpio10 5 0 &gpio10 2 0 &gpio10 4 0 &gpio10 3 0 &gpio11 2 0>;
		huawei,gpio-ctrl-types = "reset", "powerdown", "dphy_txrxz", "dphy_rstzcal", "cam_1v05_en", "cam_1v2_en", "cam_1v8_en", "cam_2v85_en", "cam_vcm_2v85_en", "cam_vcm_power";
		status = "disable";
	};

	huawei,imx230 {
		huawei,is_fpga = <1>;
		gpios = <&gpio11 3 0 &gpio11 1 0 &gpio10 7 0 &gpio11 0 0 &gpio10 6 0 &gpio10 5 0 &gpio10 2 0 &gpio10 4 0 &gpio10 3 0 &gpio11 2 0>;
		huawei,gpio-ctrl-types = "reset", "powerdown", "dphy_txrxz", "dphy_rstzcal", "cam_1v05_en", "cam_1v2_en", "cam_1v8_en", "cam_2v85_en", "cam_vcm_2v85_en", "cam_vcm_power";
		status = "disable";
	};

	huawei,imx278 {
		huawei,is_fpga = <1>;
		gpios = <&gpio11 3 0 &gpio11 1 0 &gpio10 7 0 &gpio11 0 0 &gpio10 6 0 &gpio10 5 0 &gpio10 2 0 &gpio10 4 0 &gpio10 3 0 &gpio11 2 0>;
		huawei,gpio-ctrl-types = "reset", "powerdown", "dphy_txrxz", "dphy_rstzcal", "cam_1v05_en", "cam_1v2_en", "cam_1v8_en", "cam_2v85_en", "cam_vcm_2v85_en", "cam_vcm_power";
		status = "disabled";
    };

	huawei,imx298 {
		huawei,is_fpga = <0>;
		huawei,csi_index = <0 2>;
		huawei,i2c_index = <0 2>;
        clocks = <&clk_gate_isp_snclk0>;
        clock-names = "clk_isp_snclk0";
        huawei,mclk = <24000000>;
        avdd-supply = <&ldo13>;
        dvdd-supply = <&ldo32>;

        avdd2-supply = <&ldo19>;
        dvdd2-supply = <&ldo20>;
        vcm-supply = <&ldo25>;
        huawei,ldo-names = "avdd", "dvdd", "avdd2", "dvdd2", "vcm";

        gpios = <&gpio18 2 0 &gpio6 3 0 &gpio6 4 0 &gpio4 2 0>;
        huawei,gpio-ctrl-types = "suspend", "ldo_en", "reset", "ois";
		status = "ok";
    };

	nfc_exist{
		status = "ok";
		nfc_exist_flag = "1";
		hisee_exist_flag = "1";
	};

	reserved-memory {
	        tui-mem{
			status = "ok";
		};
	};

	fingerprint {
			compatible = "fpc,fingerprint";
			spi-max-frequency = <5000000>;
			fingerprint,product = "hi3660";

			fingerprint,moduleid_high = "CT";
			fingerprint,moduleid_low = "OF";
			fingerprint,moduleid_float = "NN";

			fingerprint,reset_gpio = <46>;
			fingerprint,cs_gpio = <218>;
			fingerprint,irq_gpio = <207>;
			fingerprint,moduleid_gpio = <49>;
			fingerprint,fpc2050=<1>;
    };

};
